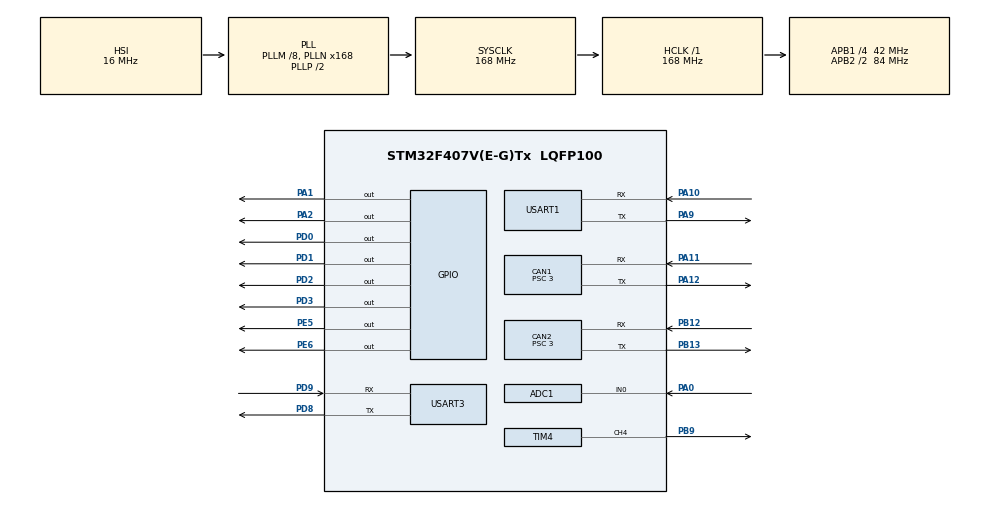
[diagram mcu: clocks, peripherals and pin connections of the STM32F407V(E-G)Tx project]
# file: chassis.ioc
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ADC1.Channel-1\#ChannelRegularConversion=ADC_CHANNEL_0
ADC1.NbrOfConversionFlag=1
ADC1.Rank-1\#ChannelRegularConversion=1
ADC1.SamplingTime-1\#ChannelRegularConversion=ADC_SAMPLETIME_3CYCLES
ADC1.master=1
CAN1.BS1=CAN_BS1_9TQ
CAN1.BS2=CAN_BS2_4TQ
CAN1.CalculateTimeQuantum=71.42857142857143
CAN1.Prescaler=3
CAN2.BS1=CAN_BS1_9TQ
CAN2.BS2=CAN_BS2_4TQ
CAN2.CalculateTimeQuantum=71.42857142857143
CAN2.Prescaler=3
Dma.Request0=USART1_RX
Dma.Request1=USART1_TX
Dma.USART1_RX.0.Direction=DMA_PERIPH_TO_MEMORY
Dma.USART1_RX.0.FIFOMode=DMA_FIFOMODE_DISABLE
Dma.USART1_RX.0.Instance=DMA2_Stream2
Dma.USART1_RX.0.MemDataAlignment=DMA_MDATAALIGN_BYTE
Dma.USART1_RX.0.MemInc=DMA_MINC_ENABLE
Dma.USART1_RX.0.Mode=DMA_NORMAL
Dma.USART1_RX.0.PeriphDataAlignment=DMA_PDATAALIGN_BYTE
Dma.USART1_RX.0.PeriphInc=DMA_PINC_DISABLE
Dma.USART1_RX.0.Priority=DMA_PRIORITY_HIGH
Dma.USART1_TX.1.Direction=DMA_MEMORY_TO_PERIPH
Dma.USART1_TX.1.FIFOMode=DMA_FIFOMODE_DISABLE
Dma.USART1_TX.1.Instance=DMA2_Stream7
Dma.USART1_TX.1.MemDataAlignment=DMA_MDATAALIGN_BYTE
Dma.USART1_TX.1.MemInc=DMA_MINC_ENABLE
Dma.USART1_TX.1.Mode=DMA_NORMAL
Dma.USART1_TX.1.PeriphDataAlignment=DMA_PDATAALIGN_BYTE
Dma.USART1_TX.1.PeriphInc=DMA_PINC_DISABLE
Dma.USART1_TX.1.Priority=DMA_PRIORITY_MEDIUM
FREERTOS.INCLUDE_vTaskDelayUntil=1
FREERTOS.Tasks01=defaultTask,0,256,StartDefaultTask,Default,NULL,Dynamic,NULL,NULL;printfTask,-3,256,Printf_Task,As weak,NULL,Dynamic,NULL,NULL;chassisTask,-3,256,Chassis_Task,As weak,NULL,Dynamic,NULL,NULL;refereeUsartTas,-3,256,Referee_Usart_Task,As weak,NULL,Dynamic,NULL,NULL
FREERTOS.configMAX_PRIORITIES=16
FREERTOS.configMINIMAL_STACK_SIZE=256
Mcu.Family=STM32F4
Mcu.Name=STM32F407V(E-G)Tx
Mcu.Package=LQFP100
NVIC.CAN1_RX0_IRQn=true\:5\:0\:false\:false\:true\:true\:true\:true
NVIC.CAN2_RX0_IRQn=true\:5\:0\:false\:false\:true\:true\:true\:true
NVIC.DMA2_Stream2_IRQn=true\:5\:0\:false\:false\:true\:true\:false\:true
NVIC.DMA2_Stream7_IRQn=true\:5\:0\:false\:false\:true\:true\:false\:true
NVIC.PriorityGroup=NVIC_PRIORITYGROUP_4
NVIC.USART1_IRQn=true\:5\:0\:false\:false\:true\:true\:true\:true
PA0-WKUP.Signal=ADCx_IN0
PA1.Signal=GPIO_Output
PA10.Mode=Asynchronous
PA10.Signal=USART1_RX
PA11.Mode=Master
PA11.Signal=CAN1_RX
PA12.Mode=Master
PA12.Signal=CAN1_TX
PA2.Signal=GPIO_Output
PA9.Mode=Asynchronous
PA9.Signal=USART1_TX
PB12.Mode=Slave
PB12.Signal=CAN2_RX
PB13.Mode=Slave
PB13.Signal=CAN2_TX
PB9.Signal=S_TIM4_CH4
PD0.Signal=GPIO_Output
PD1.Signal=GPIO_Output
PD2.Signal=GPIO_Output
PD3.Signal=GPIO_Output
PD8.Mode=Asynchronous
PD8.Signal=USART3_TX
PD9.Mode=Asynchronous
PD9.Signal=USART3_RX
PE5.Signal=GPIO_Output
PE6.Signal=GPIO_Output
PH0-OSC_IN.Mode=HSE-External-Oscillator
PH0-OSC_IN.Signal=RCC_OSC_IN
PH1-OSC_OUT.Mode=HSE-External-Oscillator
PH1-OSC_OUT.Signal=RCC_OSC_OUT
ProjectManager.HeapSize=0x200
ProjectManager.StackSize=0x400
ProjectManager.TargetToolchain=MDK-ARM V5.27
RCC.48MHZClocksFreq_Value=84000000
RCC.AHBFreq_Value=168000000
RCC.APB1CLKDivider=RCC_HCLK_DIV4
RCC.APB1Freq_Value=42000000
RCC.APB1TimFreq_Value=84000000
RCC.APB2CLKDivider=RCC_HCLK_DIV2
RCC.APB2Freq_Value=84000000
RCC.APB2TimFreq_Value=168000000
RCC.CortexFreq_Value=168000000
RCC.HCLKFreq_Value=168000000
RCC.HSE_VALUE=8000000
RCC.HSI_VALUE=16000000
RCC.LSE_VALUE=32768
RCC.PLLM=8
RCC.PLLN=168
RCC.SYSCLKFreq_VALUE=168000000
RCC.SYSCLKSource=RCC_SYSCLKSOURCE_PLLCLK
RCC.VCOOutputFreq_Value=336000000
SH.ADCx_IN0.0=ADC1_IN0,IN0
SH.S_TIM4_CH4.0=TIM4_CH4,PWM Generation4 CH4
TIM4.Channel-PWM\ Generation4\ CH4=TIM_CHANNEL_4
TIM4.Period=21000-1
TIM6.Period=65535
USART1.VirtualMode=VM_ASYNC
USART3.VirtualMode=VM_ASYNC
VP_FREERTOS_VS_CMSIS_V1.Mode=CMSIS_V1
VP_TIM4_VS_ClockSourceINT.Mode=Internal
VP_TIM6_VS_ClockSourceINT.Mode=Enable_Timer
board=custom

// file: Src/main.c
/* USER CODE BEGIN Header */
/**
  ******************************************************************************
  * @file           : main.c
  * @brief          : Main program body
  ******************************************************************************
  * @attention
  *
  * <h2><center>&copy; Copyright (c) 2020 STMicroelectronics.
  * All rights reserved.</center></h2>
  *
  * This software component is licensed by ST under Ultimate Liberty license
  * SLA0044, the "License"; You may not use this file except in compliance with
  * the License. You may obtain a copy of the License at:
  *                             www.st.com/SLA0044
  *
  ******************************************************************************
  */
/* USER CODE END Header */

#include "main.h"
#include "cmsis_os.h"
#include "adc.h"
#include "can.h"
#include "dma.h"
#include "tim.h"
#include "usart.h"
#include "gpio.h"

/* USER CODE BEGIN Includes */
#include "bsp_can.h"
#include "bsp_tim.h"
#include "referee_usart.h"
#include "led.h"

/* USER CODE END Includes */

void SystemClock_Config(void);
void MX_FREERTOS_Init(void);

int main(void)
{

  /* MCU Configuration--------------------------------------------------------*/

  /* Reset of all peripherals, Initializes the Flash interface and the Systick. */
  HAL_Init();

  /* USER CODE BEGIN Init */
	int i;
	while(i<500) i++;
  /* USER CODE END Init */

  /* Configure the system clock */
  SystemClock_Config();

  /* Initialize all configured peripherals */
  MX_GPIO_Init();
  MX_DMA_Init();
  MX_USART3_UART_Init();
  MX_CAN1_Init();
  MX_CAN2_Init();
  MX_TIM6_Init();
  MX_USART1_UART_Init();
  MX_ADC1_Init();
  MX_TIM4_Init();
  /* USER CODE BEGIN 2 */
	bsp_canInit();
	BSP_delayInit();
	led_init();
	HAL_GPIO_WritePin(GPIOB, GPIO_PIN_1, GPIO_PIN_RESET);
  /* USER CODE END 2 */

  /* Call init function for freertos objects (in freertos.c) */
  MX_FREERTOS_Init();

  /* Start scheduler */
  osKernelStart();

  /* We should never get here as control is now taken by the scheduler */

  /* Infinite loop */
  while (1)
  {

  }
}

void SystemClock_Config(void)
{
  RCC_OscInitTypeDef RCC_OscInitStruct = {0};
  RCC_ClkInitTypeDef RCC_ClkInitStruct = {0};

  /** Configure the main internal regulator output voltage
  */
  __HAL_RCC_PWR_CLK_ENABLE();
  __HAL_PWR_VOLTAGESCALING_CONFIG(PWR_REGULATOR_VOLTAGE_SCALE1);
  /** Initializes the CPU, AHB and APB busses clocks
  */
  RCC_OscInitStruct.OscillatorType = RCC_OSCILLATORTYPE_HSI;
  RCC_OscInitStruct.HSIState = RCC_HSI_ON;
  RCC_OscInitStruct.HSICalibrationValue = RCC_HSICALIBRATION_DEFAULT;
  RCC_OscInitStruct.PLL.PLLState = RCC_PLL_ON;
  RCC_OscInitStruct.PLL.PLLSource = RCC_PLLSOURCE_HSI;
  RCC_OscInitStruct.PLL.PLLM = 8;
  RCC_OscInitStruct.PLL.PLLN = 168;
  RCC_OscInitStruct.PLL.PLLP = RCC_PLLP_DIV2;
  RCC_OscInitStruct.PLL.PLLQ = 4;
  if (HAL_RCC_OscConfig(&RCC_OscInitStruct) != HAL_OK)
  {
    Error_Handler();
  }
  /** Initializes the CPU, AHB and APB busses clocks
  */
  RCC_ClkInitStruct.ClockType = RCC_CLOCKTYPE_HCLK|RCC_CLOCKTYPE_SYSCLK
                              |RCC_CLOCKTYPE_PCLK1|RCC_CLOCKTYPE_PCLK2;
  RCC_ClkInitStruct.SYSCLKSource = RCC_SYSCLKSOURCE_PLLCLK;
  RCC_ClkInitStruct.AHBCLKDivider = RCC_SYSCLK_DIV1;
  RCC_ClkInitStruct.APB1CLKDivider = RCC_HCLK_DIV4;
  RCC_ClkInitStruct.APB2CLKDivider = RCC_HCLK_DIV2;

  if (HAL_RCC_ClockConfig(&RCC_ClkInitStruct, FLASH_LATENCY_5) != HAL_OK)
  {
    Error_Handler();
  }
}

void Error_Handler(void)
{
}

/************************ (C) COPYRIGHT STMicroelectronics *****END OF FILE****/

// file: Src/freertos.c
/* USER CODE BEGIN Header */
/**
  ******************************************************************************
  * File Name          : freertos.c
  * Description        : Code for freertos applications
  ******************************************************************************
  * @attention
  *
  * <h2><center>&copy; Copyright (c) 2020 STMicroelectronics.
  * All rights reserved.</center></h2>
  *
  * This software component is licensed by ST under Ultimate Liberty license
  * SLA0044, the "License"; You may not use this file except in compliance with
  * the License. You may obtain a copy of the License at:
  *                             www.st.com/SLA0044
  *
  ******************************************************************************
  */
/* USER CODE END Header */

#include "FreeRTOS.h"
#include "task.h"
#include "main.h"
#include "cmsis_os.h"

osThreadId defaultTaskHandle;
osThreadId printfTaskHandle;
osThreadId chassisTaskHandle;
osThreadId refereeUsartTasHandle;

void StartDefaultTask(void const * argument);
void Printf_Task(void const * argument);
void Chassis_Task(void const * argument);
void Referee_Usart_Task(void const * argument);

void MX_FREERTOS_Init(void); /* (MISRA C 2004 rule 8.1) */

/* GetIdleTaskMemory prototype (linked to static allocation support) */
void vApplicationGetIdleTaskMemory( StaticTask_t **ppxIdleTaskTCBBuffer, StackType_t **ppxIdleTaskStackBuffer, uint32_t *pulIdleTaskStackSize );

/* USER CODE BEGIN GET_IDLE_TASK_MEMORY */
static StaticTask_t xIdleTaskTCBBuffer;
static StackType_t xIdleStack[configMINIMAL_STACK_SIZE];

void vApplicationGetIdleTaskMemory( StaticTask_t **ppxIdleTaskTCBBuffer, StackType_t **ppxIdleTaskStackBuffer, uint32_t *pulIdleTaskStackSize )
{
  *ppxIdleTaskTCBBuffer = &xIdleTaskTCBBuffer;
  *ppxIdleTaskStackBuffer = &xIdleStack[0];
  *pulIdleTaskStackSize = configMINIMAL_STACK_SIZE;
  /* place for user code */
}
/* USER CODE END GET_IDLE_TASK_MEMORY */

void MX_FREERTOS_Init(void) {

  /* Create the thread(s) */
  /* definition and creation of defaultTask */
  osThreadDef(defaultTask, StartDefaultTask, osPriorityNormal, 0, 256);
  defaultTaskHandle = osThreadCreate(osThread(defaultTask), NULL);

  /* definition and creation of printfTask */
  osThreadDef(printfTask, Printf_Task, osPriorityIdle, 0, 256);
  printfTaskHandle = osThreadCreate(osThread(printfTask), NULL);

  /* definition and creation of chassisTask */
  osThreadDef(chassisTask, Chassis_Task, osPriorityIdle, 0, 256);
  chassisTaskHandle = osThreadCreate(osThread(chassisTask), NULL);

  /* definition and creation of refereeUsartTas */
  osThreadDef(refereeUsartTas, Referee_Usart_Task, osPriorityIdle, 0, 256);
  refereeUsartTasHandle = osThreadCreate(osThread(refereeUsartTas), NULL);

}

void StartDefaultTask(void const * argument)
{
  for(;;)
  {
    osDelay(1);
  }
}

__weak void Printf_Task(void const * argument)
{
  for(;;)
  {
    osDelay(1);
  }
}

__weak void Chassis_Task(void const * argument)
{
  for(;;)
  {
    osDelay(1);
  }
}

__weak void Referee_Usart_Task(void const * argument)
{
  for(;;)
  {
    osDelay(1);
  }
}

/************************ (C) COPYRIGHT STMicroelectronics *****END OF FILE****/
